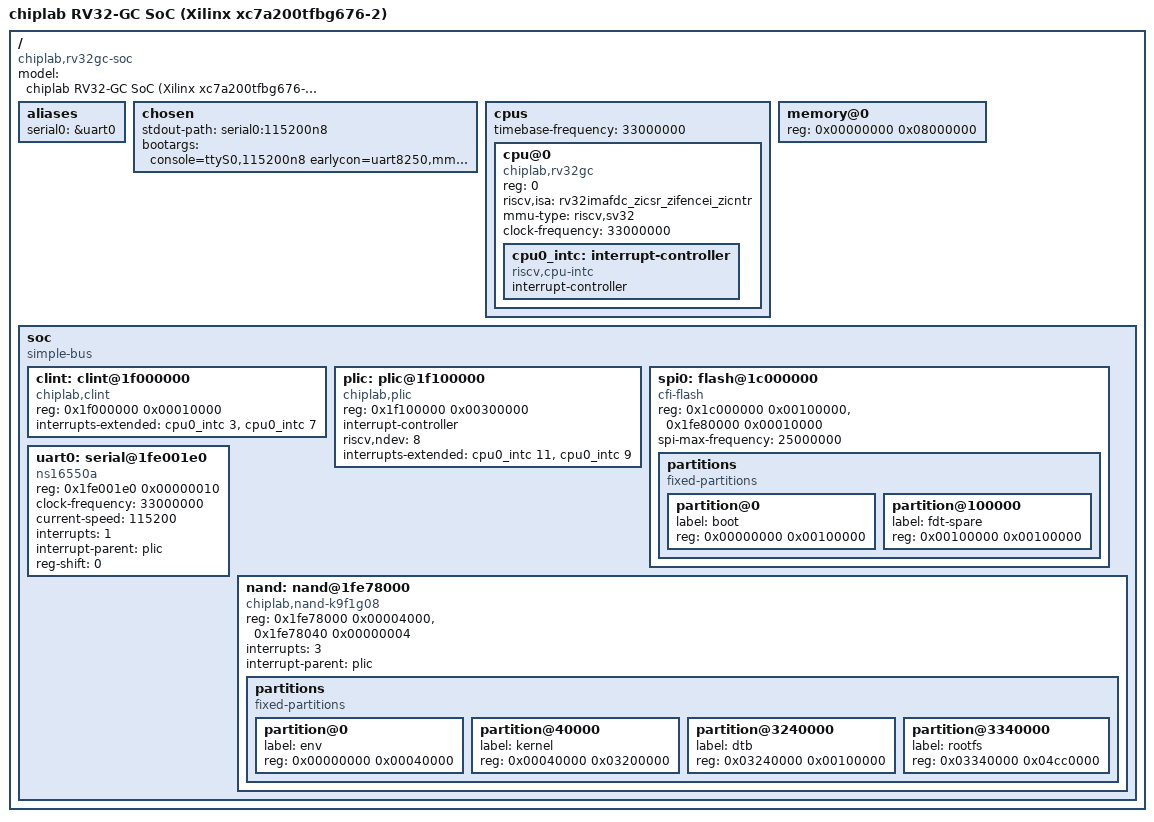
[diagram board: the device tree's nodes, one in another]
/*
 * rv32gc-chiplab.dts —— RV32-GC 核 + chiplab(xc7a200tfbg676-2) 平台的设备树
 * ============================================================================
 * 本文件是「2A-7c：DTS/OpenSBI 内存映射声明」的交付物，地址**必须**与 RTL 常量一致：
 *   rtl/pkg/rv32gc_defs.vh 的 DDR_BASE/DDR_SIZE、SPI_XIP_BASE、CLINT_BASE、PLIC_BASE
 *   scripts/check_dts.sh 会做「DTS ↔ RTL 常量」的交叉校验（仿真可验证部分），改一处漏一处会 FAIL。
 *
 * 与 chiplab 参考（LA32R）DTS 的差异（本核的架构决策，见 AGENT.md §2）：
 *   · DDR：`0x0000_0000` 起 128 MiB —— 与平台 AXI 默认从设备一致（D15：不改互连编址）；
 *   · CLINT/PLIC 是**核内实现**（D5），不在互连上，故放 `0x1F00_0000/0x1F10_0000`；
 *   · 复位取指窗口是 SPI-XIP `0x1C00_0000`（D16），没有片上 boot ROM；
 *     所以 `/chosen` 里不需要 OpenSBI 的 `fdt` 重定位约定，SPI 小引导负责把自己搬到 DDR 再跳转。
 * ============================================================================
 */

/dts-v1/;

/ {
    #address-cells = <1>;
    #size-cells    = <1>;
    compatible     = "chiplab,rv32gc-soc";
    model          = "chiplab RV32-GC SoC (Xilinx xc7a200tfbg676-2)";

    aliases {
        serial0 = &uart0;
    };

    chosen {
        /* SPI 小引导把控制权交给 DDR 主镜像后，OpenSBI/U-Boot 继续用这份 DTB */
        stdout-path = "serial0:115200n8";
        bootargs    = "console=ttyS0,115200n8 earlycon=uart8250,mmio,0x1fe001e0 rdinit=/sbin/init";
    };

    cpus {
        #address-cells = <1>;
        #size-cells    = <0>;
        timebase-frequency = <33000000>;   /* mtime 频率 = cpu_clk = 33 MHz（用户第 8 轮拍板：上板用 33 MHz）*/

        cpu@0 {
            device_type        = "cpu";
            reg                = <0>;
            status             = "okay";
            compatible         = "chiplab,rv32gc", "riscv";
            riscv,isa          = "rv32imafdc_zicsr_zifencei_zicntr";
            mmu-type           = "riscv,sv32";
            clock-frequency    = <33000000>;   /* cpu_clk = uncore_clk = 33 MHz（用户拍板；clk_pll_33 clk_out1）*/

            cpu0_intc: interrupt-controller {
                #interrupt-cells = <1>;
                interrupt-controller;
                compatible = "riscv,cpu-intc";
            };
        };
    };

    /* ---- 128 MiB DDR3：AXI 默认从设备，主镜像按 0x0 链接（D15/D16） ---- */
    memory@0 {
        device_type = "memory";
        reg         = <0x00000000 0x08000000>;
    };

    soc {
        #address-cells = <1>;
        #size-cells    = <1>;
        compatible     = "simple-bus";
        ranges;

        /* ---- 核内 CLINT（D5）：0x1F00_0000 —— msip/mtimecmp/mtime ---- */
        clint: clint@1f000000 {
            compatible          = "chiplab,clint", "sifive,clint0";   /* riscv,clint0 已被 binding 标 deprecated */
            reg                 = <0x1f000000 0x00010000>;
            interrupts-extended = <&cpu0_intc 3>,   /* M 软件中断 */
                                  <&cpu0_intc 7>;   /* M 定时器中断 */
        };

        /* ---- 核内 PLIC（D5）：SiFive PLIC 1.0.0 布局，8 源 2 上下文 ---- */
        plic: plic@1f100000 {
            compatible          = "chiplab,plic", "sifive,plic-1.0.0"; /* riscv,plic0 已被 binding 标 deprecated */
            reg                 = <0x1f100000 0x00300000>;   /* 含 0x20_0000 threshold / 0x20_1000 claim */
            #interrupt-cells    = <1>;
            #address-cells      = <0>;
            interrupt-controller;
            riscv,ndev          = <8>;
            interrupts-extended = <&cpu0_intc 11>,  /* M 外部中断 */
                                  <&cpu0_intc 9>;   /* S 外部中断 */
        };

        /* ---- SPI NOR（S25FL128SAGMFI001，16 MiB）：复位取指 XIP 窗口 1 MiB + 别名 64 KiB ---- */
        spi0: flash@1c000000 {
            /* 复位取指窗口：**内存映射只读 flash**。本阶段只做 XIP 读，
             * SPI 控制器的寄存器接口未建模；jedec,spi-nor 需挂在 SPI 控制器之下，
             * 直挂 soc 不符 binding 模型，故改用内存映射 flash 口径（见 08 知识文档 §2）。 */
            compatible   = "cfi-flash";
            reg          = <0x1c000000 0x00100000>,   /* XIP 窗口：SPI_XIP_BASE，1 MiB（D16） */
                           <0x1fe80000 0x00010000>;   /* 别名窗口：SPI_XIP_ALIAS_BASE */
            spi-max-frequency = <25000000>;
            #address-cells    = <1>;
            #size-cells       = <1>;

            partitions {
                compatible = "fixed-partitions";
                #address-cells = <1>;
                #size-cells    = <1>;

                partition@0 {
                    label = "boot";
                    reg   = <0x00000000 0x00100000>;   /* SPI 小引导镜像 ≤1 MiB（2A-7b 判据） */
                };
                partition@100000 {
                    label = "fdt-spare";
                    reg   = <0x00100000 0x00100000>;
                };
            };
        };

        /* ---- UART0：16550 寄存器块在窗口 +0x1E0（uncore 33 MHz，PLIC 源 1） ---- */
        uart0: serial@1fe001e0 {
            compatible        = "ns16550a";
            reg               = <0x1fe001e0 0x00000010>;
            clock-frequency   = <33000000>;
            current-speed     = <115200>;
            interrupts        = <1>;
            interrupt-parent  = <&plic>;
            reg-shift         = <0>;   /* 参考 loongson32_ls.dts 的 UART 节点不给 reg-shift/reg-io-width
                                        * ⇒ 二者取默认（0 / 1 字节步进）。写 4 会让 8250 驱动按 32 位 MMIO
                                        * 访问，与本平台字节步进的寄存器口不符。 */
        };

        /* ---- NAND 控制器（K9F1G08U0C，128 MiB；数据口 = 基址 +0x40） ---- */
        nand: nand@1fe78000 {
            compatible       = "chiplab,nand-k9f1g08";
            reg              = <0x1fe78000 0x00004000>,   /* 基址（APB addr[19:14]!=0 通道） */
                               <0x1fe78040 0x00000004>;   /* 数据口 */
            interrupts       = <3>;
            interrupt-parent = <&plic>;
            #address-cells   = <1>;
            #size-cells      = <1>;

            partitions {
                compatible = "fixed-partitions";
                #address-cells = <1>;
                #size-cells    = <1>;

                partition@0 {                    /* U-Boot 环境：ENV_OFFSET=0, ENV_SIZE=0x40000 */
                    label = "env";
                    reg   = <0x00000000 0x00040000>;
                };
                partition@40000 {                /* Linux 内核 Image（只读） */
                    label = "kernel";
                    reg   = <0x00040000 0x03200000>;
                };
                partition@3240000 {              /* 设备树 blob */
                    label = "dtb";
                    reg   = <0x03240000 0x00100000>;
                };
                partition@3340000 {              /* UBIFS 根文件系统（余下 ≈76.75 MiB） */
                    label = "rootfs";
                    reg   = <0x03340000 0x04cc0000>;
                };
            };
        };
    };
};
